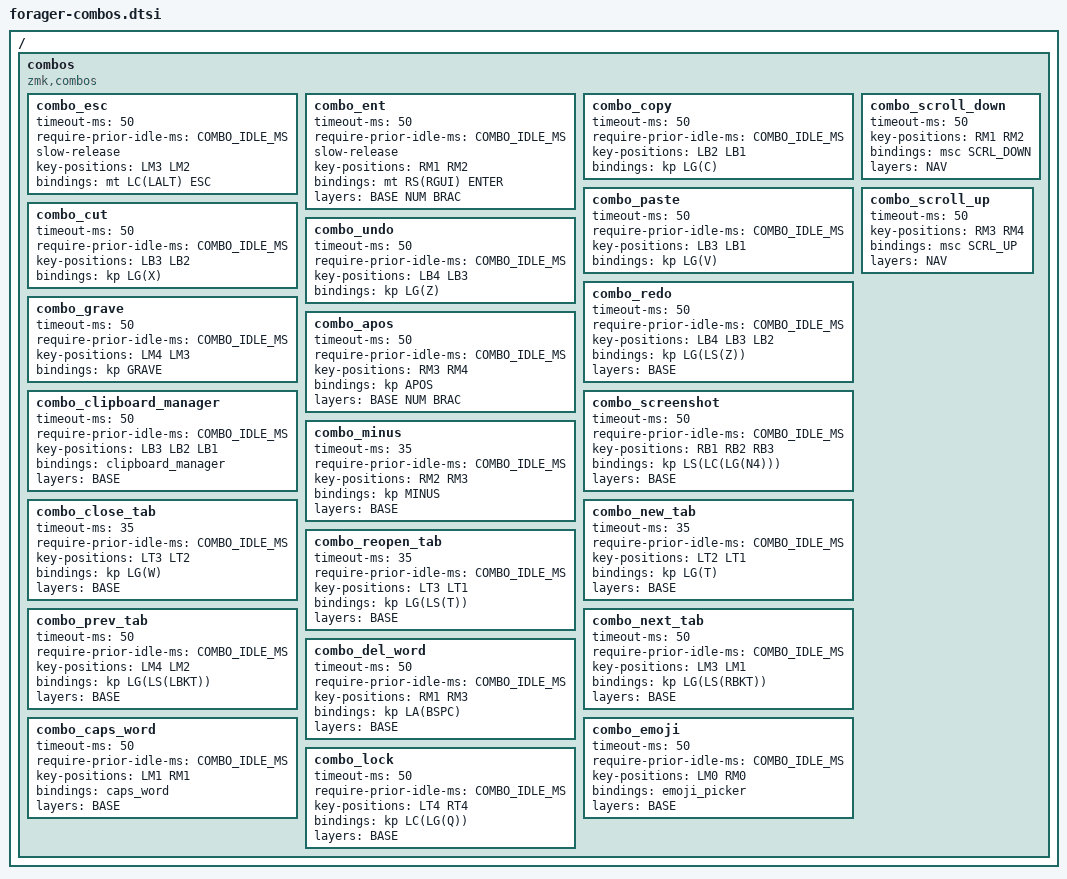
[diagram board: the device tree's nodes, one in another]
/*                   KEY POSITIONS
    ╭──────────────────────┬──────────────────────╮
    │  LT4 LT3 LT2 LT1 LT0 │ RT0 RT1 RT2 RT3 RT4  │
    │  LM4 LM3 LM2 LM1 LM0 │ RM0 RM1 RM2 RM3 RM4  │
    │  LB4 LB3 LB2 LB1 LB0 │ RB0 RB1 RB2 RB3 RB4  │
    ╰───────────╮  LH1 LH0 │ RH0 RH1  ╭───────────╯
                ╰──────────┴──────────╯

*/

// A combo only fires if no other key was pressed this shortly before it, so
// fast rolls over two neighbouring keys ("io", "ui", "xc", ...) type letters
// instead of triggering it. Too high and a combo pressed right after a word
// types its two letters instead; too low and rolls trigger combos again.
#define COMBO_IDLE_MS 125

/ {
    combos {
        compatible = "zmk,combos";
        combo_esc {
            timeout-ms = <50>;
            require-prior-idle-ms = <COMBO_IDLE_MS>;
            slow-release;
            key-positions = <LM3 LM2>;
            bindings = <&mt LC(LALT) ESC>;
        };
        // Not on NAV: there J+K scrolls instead (combo_scroll_down).
        // slow-release (here and on esc): the modifier of the hold stays
        // until both keys are up, not just the first.
        combo_ent {
            timeout-ms = <50>;
            require-prior-idle-ms = <COMBO_IDLE_MS>;
            slow-release;
            key-positions = <RM1 RM2>;
            bindings = <&mt RS(RGUI) ENTER>;
            layers = <BASE NUM BRAC>;
        };
        combo_copy {
            timeout-ms = <50>;
            require-prior-idle-ms = <COMBO_IDLE_MS>;
            key-positions = <LB2 LB1>;
            bindings = <&kp LG(C)>;
        };
        combo_paste {
            timeout-ms = <50>;
            require-prior-idle-ms = <COMBO_IDLE_MS>;
            key-positions = <LB3 LB1>;
            bindings = <&kp LG(V)>;
        };
        combo_cut {
            timeout-ms = <50>;
            require-prior-idle-ms = <COMBO_IDLE_MS>;
            key-positions = <LB3 LB2>;
            bindings = <&kp LG(X)>;
        };
        combo_undo {
            timeout-ms = <50>;
            require-prior-idle-ms = <COMBO_IDLE_MS>;
            key-positions = <LB4 LB3>;
            bindings = <&kp LG(Z)>;
        };
        combo_redo {
            timeout-ms = <50>;
            require-prior-idle-ms = <COMBO_IDLE_MS>;
            key-positions = <LB4 LB3 LB2>;
            bindings = <&kp LG(LS(Z))>;
            layers = <BASE>;
        };
        combo_grave {
            timeout-ms = <50>;
            require-prior-idle-ms = <COMBO_IDLE_MS>;
            key-positions = <LM4 LM3>;
            bindings = <&kp GRAVE>;
        };
        // Not on NAV: there L+; scrolls instead (combo_scroll_up)
        combo_apos {
            timeout-ms = <50>;
            require-prior-idle-ms = <COMBO_IDLE_MS>;
            key-positions = <RM3 RM4>;
            bindings = <&kp APOS>;
            layers = <BASE NUM BRAC>;
        };
        // NAV only: hold the two keys to keep scrolling, let go of either
        // to stop. Needs CONFIG_ZMK_POINTING on the dongle.
        combo_scroll_down {
            timeout-ms = <50>;
            key-positions = <RM1 RM2>;
            bindings = <&msc SCRL_DOWN>;
            layers = <NAV>;
        };
        combo_scroll_up {
            timeout-ms = <50>;
            key-positions = <RM3 RM4>;
            bindings = <&msc SCRL_UP>;
            layers = <NAV>;
        };
        combo_clipboard_manager {
            timeout-ms = <50>;
            require-prior-idle-ms = <COMBO_IDLE_MS>;
            key-positions = <LB3 LB2 LB1>;
            bindings = <&clipboard_manager>;
            layers = <BASE>;
        };
        combo_screenshot {
            timeout-ms = <50>;
            require-prior-idle-ms = <COMBO_IDLE_MS>;
            key-positions = <RB1 RB2 RB3>;
            bindings = <&kp LS(LC(LG(N4)))>;
            layers = <BASE>;
        };

        // ---- macOS helpers, BASE only ----
        // None of them pairs an inner-column key (T G B / Y H N) with its
        // neighbour: that would mean pressing an index-finger key with the
        // middle finger. Pairs that are common letter rolls ("we", "er",
        // "wr", "kl") get a shorter window.

        // K+L
        combo_minus {
            timeout-ms = <35>;
            require-prior-idle-ms = <COMBO_IDLE_MS>;
            key-positions = <RM2 RM3>;
            bindings = <&kp MINUS>;
            layers = <BASE>;
        };
        // Tabs on the left top row: W+E close, E+R new, W+R reopen closed
        combo_close_tab {
            timeout-ms = <35>;
            require-prior-idle-ms = <COMBO_IDLE_MS>;
            key-positions = <LT3 LT2>;
            bindings = <&kp LG(W)>;
            layers = <BASE>;
        };
        combo_new_tab {
            timeout-ms = <35>;
            require-prior-idle-ms = <COMBO_IDLE_MS>;
            key-positions = <LT2 LT1>;
            bindings = <&kp LG(T)>;
            layers = <BASE>;
        };
        combo_reopen_tab {
            timeout-ms = <35>;
            require-prior-idle-ms = <COMBO_IDLE_MS>;
            key-positions = <LT3 LT1>;
            bindings = <&kp LG(LS(T))>;
            layers = <BASE>;
        };
        // ... and on the home row: A+D previous tab, S+F next tab. BASE only:
        // on NAV these keys are held modifiers.
        combo_prev_tab {
            timeout-ms = <50>;
            require-prior-idle-ms = <COMBO_IDLE_MS>;
            key-positions = <LM4 LM2>;
            bindings = <&kp LG(LS(LBKT))>;
            layers = <BASE>;
        };
        combo_next_tab {
            timeout-ms = <50>;
            require-prior-idle-ms = <COMBO_IDLE_MS>;
            key-positions = <LM3 LM1>;
            bindings = <&kp LG(LS(RBKT))>;
            layers = <BASE>;
        };
        // J+L delete word
        combo_del_word {
            timeout-ms = <50>;
            require-prior-idle-ms = <COMBO_IDLE_MS>;
            key-positions = <RM1 RM3>;
            bindings = <&kp LA(BSPC)>;
            layers = <BASE>;
        };
        // Across hands: F+J caps word, G+H emoji picker, Q+P lock screen
        combo_caps_word {
            timeout-ms = <50>;
            require-prior-idle-ms = <COMBO_IDLE_MS>;
            key-positions = <LM1 RM1>;
            bindings = <&caps_word>;
            layers = <BASE>;
        };
        combo_emoji {
            timeout-ms = <50>;
            require-prior-idle-ms = <COMBO_IDLE_MS>;
            key-positions = <LM0 RM0>;
            bindings = <&emoji_picker>;
            layers = <BASE>;
        };
        combo_lock {
            timeout-ms = <50>;
            require-prior-idle-ms = <COMBO_IDLE_MS>;
            key-positions = <LT4 RT4>;
            bindings = <&kp LC(LG(Q))>;
            layers = <BASE>;
        };
    };
};
